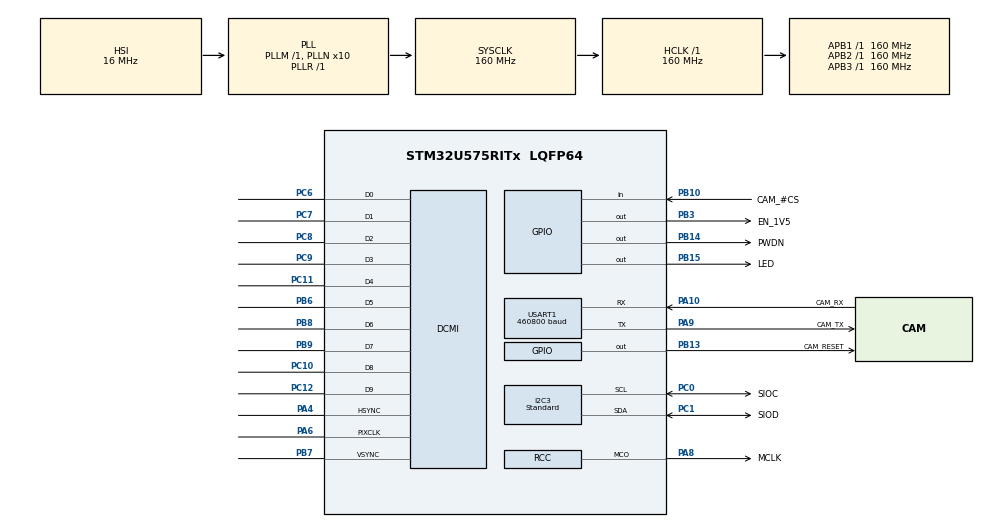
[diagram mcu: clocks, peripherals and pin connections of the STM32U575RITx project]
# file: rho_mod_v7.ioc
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CORTEX_M33_NS.userName=CORTEX_M33
DCMI.CaptureRate=DCMI_CR_ALL_FRAME
DCMI.HSPolarity=DCMI_HSPOLARITY_LOW
DCMI.JPEGMode=DCMI_JPEG_DISABLE
DCMI.LineSelectMode=DCMI_LSM_ALL
DCMI.PCKPolarity=DCMI_PCKPOLARITY_RISING
DCMI.VSPolarity=DCMI_VSPOLARITY_HIGH
GPDMA1.ChannelPRIV_GPDMACH15=DMA_CHANNEL_PRIV
GPDMA1.LINKALLOCATEDPORT_GPDMACH15=DMA_LINK_ALLOCATED_PORT1
GPDMA1.LINKEDLISTMODE_GPDMACH15=DMA_LINKEDLIST_CIRCULAR
GPDMA1.PRIORITY_LL_GPDMACH15=DMA_HIGH_PRIORITY
GPDMA1.TRANSFEREVENTMODE_LL_GPDMACH15=DMA_TCEM_LAST_LL_ITEM_TRANSFER
I2C3.I2C_Speed_Mode=I2C_Standard
I2C3.Timing=0x30909DEC
Linkedlist.MDMA_Channel0.GP_SW.0.ADDRESSING2D=ENABLE
Linkedlist.MDMA_Channel0.GP_SW.0.BlkDestAddrOffset=0
Linkedlist.MDMA_Channel0.GP_SW.0.BlkHWRequest=DMA_BREQ_SINGLE_BURST
Linkedlist.MDMA_Channel0.GP_SW.0.BlkSrcAddrOffset=0
Linkedlist.MDMA_Channel0.GP_SW.0.DataHandling=NONE
Linkedlist.MDMA_Channel0.GP_SW.0.DataSize=0
Linkedlist.MDMA_Channel0.GP_SW.0.DestAddrOffset=0
Linkedlist.MDMA_Channel0.GP_SW.0.DestBurstLength=1
Linkedlist.MDMA_Channel0.GP_SW.0.DestDataWidth=DMA_DEST_DATAWIDTH_WORD
Linkedlist.MDMA_Channel0.GP_SW.0.DestInc=DMA_DINC_INCREMENTED
Linkedlist.MDMA_Channel0.GP_SW.0.Direction=DMA_PERIPH_TO_MEMORY
Linkedlist.MDMA_Channel0.GP_SW.0.DstAddress=0
Linkedlist.MDMA_Channel0.GP_SW.0.Instance=MDMA_Channel0
Linkedlist.MDMA_Channel0.GP_SW.0.LL_CIRCULARNODE=DCMINode1
Linkedlist.MDMA_Channel0.GP_SW.0.LL_MASTERDMA=GPDMA2D
Linkedlist.MDMA_Channel0.GP_SW.0.LL_NAME=DCMIQueue
Linkedlist.MDMA_Channel0.GP_SW.0.LL_TYPE=CIRCULAR
Linkedlist.MDMA_Channel0.GP_SW.0.NODE_NAME=DCMINode1
Linkedlist.MDMA_Channel0.GP_SW.0.RepeatCount=1
Linkedlist.MDMA_Channel0.GP_SW.0.Requestforcodegen=GPDMA1_REQUEST_DCMI
Linkedlist.MDMA_Channel0.GP_SW.0.SrcAddrOffset=0
Linkedlist.MDMA_Channel0.GP_SW.0.SrcAddress=0
Linkedlist.MDMA_Channel0.GP_SW.0.SrcBurstLength=1
Linkedlist.MDMA_Channel0.GP_SW.0.SrcDataWidth=DMA_SRC_DATAWIDTH_WORD
Linkedlist.MDMA_Channel0.GP_SW.0.SrcInc=DMA_SINC_FIXED
Linkedlist.MDMA_Channel0.GP_SW.0.TransferAllocatedPortSrc=DMA_SRC_ALLOCATED_PORT0
Linkedlist.MDMA_Channel0.GP_SW.0.TransferEventMode=DMA_TCEM_BLOCK_TRANSFER
Linkedlist.MDMA_Channel0.GP_SW.0.TriggerPolarity=DMA_TRIG_POLARITY_MASKED
Linkedlist.MDMA_Channel0.GP_SW.1.ADDRESSING2D=ENABLE
Linkedlist.MDMA_Channel0.GP_SW.1.BlkDestAddrOffset=0
Linkedlist.MDMA_Channel0.GP_SW.1.BlkHWRequest=DMA_BREQ_SINGLE_BURST
Linkedlist.MDMA_Channel0.GP_SW.1.BlkSrcAddrOffset=0
Linkedlist.MDMA_Channel0.GP_SW.1.DataHandling=NONE
Linkedlist.MDMA_Channel0.GP_SW.1.DataSize=0
Linkedlist.MDMA_Channel0.GP_SW.1.DestAddrOffset=0
Linkedlist.MDMA_Channel0.GP_SW.1.DestBurstLength=1
Linkedlist.MDMA_Channel0.GP_SW.1.DestDataWidth=DMA_DEST_DATAWIDTH_WORD
Linkedlist.MDMA_Channel0.GP_SW.1.DestInc=DMA_DINC_INCREMENTED
Linkedlist.MDMA_Channel0.GP_SW.1.Direction=DMA_PERIPH_TO_MEMORY
Linkedlist.MDMA_Channel0.GP_SW.1.DstAddress=0
Linkedlist.MDMA_Channel0.GP_SW.1.Instance=MDMA_Channel0
Linkedlist.MDMA_Channel0.GP_SW.1.LL_CIRCULARNODE=DCMINode1
Linkedlist.MDMA_Channel0.GP_SW.1.LL_MASTERDMA=GPDMA2D
Linkedlist.MDMA_Channel0.GP_SW.1.LL_NAME=DCMIQueue
Linkedlist.MDMA_Channel0.GP_SW.1.LL_TYPE=CIRCULAR
Linkedlist.MDMA_Channel0.GP_SW.1.NODE_NAME=DCMINode2
Linkedlist.MDMA_Channel0.GP_SW.1.RepeatCount=1
Linkedlist.MDMA_Channel0.GP_SW.1.Requestforcodegen=GPDMA1_REQUEST_DCMI
Linkedlist.MDMA_Channel0.GP_SW.1.SrcAddrOffset=0
Linkedlist.MDMA_Channel0.GP_SW.1.SrcAddress=0
Linkedlist.MDMA_Channel0.GP_SW.1.SrcBurstLength=1
Linkedlist.MDMA_Channel0.GP_SW.1.SrcDataWidth=DMA_SRC_DATAWIDTH_WORD
Linkedlist.MDMA_Channel0.GP_SW.1.SrcInc=DMA_SINC_FIXED
Linkedlist.MDMA_Channel0.GP_SW.1.TransferAllocatedPortSrc=DMA_SRC_ALLOCATED_PORT0
Linkedlist.MDMA_Channel0.GP_SW.1.TransferEventMode=DMA_TCEM_BLOCK_TRANSFER
Linkedlist.MDMA_Channel0.GP_SW.1.TriggerPolarity=DMA_TRIG_POLARITY_MASKED
Linkedlist.MDMA_Channel0.Request0=GP_SW
Linkedlist.MDMA_Channel0.Request1=GP_SW
Linkedlist.MDMA_Channel0.RequestsNb=2
Linkedlist.RequestSet0=MDMA_Channel0
Linkedlist.RequestSetsNb=1
Mcu.Family=STM32U5
Mcu.Name=STM32U575RITx
Mcu.Package=LQFP64
NVIC.DCMI_PSSI_IRQn=true\:0\:0\:false\:false\:true\:true\:true\:true
NVIC.GPDMA1_Channel15_IRQn=true\:0\:0\:false\:false\:true\:true\:true\:true
NVIC.PriorityGroup=NVIC_PRIORITYGROUP_4
PA10.GPIO_Label=CAM_RX
PA10.Mode=Asynchronous
PA10.Signal=USART1_RX
PA13\ (JTMS/SWDIO).Mode=Serial_Wire
PA13\ (JTMS/SWDIO).Signal=DEBUG_JTMS-SWDIO
PA14\ (JTCK/SWCLK).Mode=Serial_Wire
PA14\ (JTCK/SWCLK).Signal=DEBUG_JTCK-SWCLK
PA4.GPIO_Speed=GPIO_SPEED_FREQ_HIGH
PA4.Mode=Slave_10_bits_External_Synchro
PA4.Signal=DCMI_HSYNC
PA6.GPIO_PuPd=GPIO_NOPULL
PA6.GPIO_Speed=GPIO_SPEED_FREQ_HIGH
PA6.Mode=Slave_10_bits_External_Synchro
PA6.Signal=DCMI_PIXCLK
PA8.GPIO_Label=MCLK
PA8.GPIO_Speed_HighF_Default=GPIO_SPEED_FREQ_VERY_HIGH
PA8.Mode=Clock-out
PA8.Signal=RCC_MCO
PA9.GPIO_Label=CAM_TX
PA9.Mode=Asynchronous
PA9.Signal=USART1_TX
PB10.GPIO_Label=CAM_\#CS
PB10.GPIO_PuPd=GPIO_PULLDOWN
PB10.Signal=GPIO_Input
PB13.GPIO_Label=CAM_RESET
PB13.GPIO_PuPd=GPIO_PULLDOWN
PB13.Signal=GPIO_Output
PB14.GPIO_Label=PWDN
PB14.GPIO_PuPd=GPIO_PULLUP
PB14.Signal=GPIO_Output
PB15.GPIO_Label=LED
PB15.GPIO_PuPd=GPIO_PULLDOWN
PB15.Signal=GPIO_Output
PB3\ (JTDO/TRACESWO).GPIO_Label=EN_1V5
PB3\ (JTDO/TRACESWO).Signal=GPIO_Output
PB6.GPIO_FM6=SYSCFG_FASTMODEPLUS_PB6
PB6.GPIO_PuPd=GPIO_NOPULL
PB6.GPIO_Speed=GPIO_SPEED_FREQ_HIGH
PB6.Mode=Slave_10_bits_External_Synchro
PB6.Signal=DCMI_D5
PB7.GPIO_FM6=__NULL
PB7.GPIO_FM7=SYSCFG_FASTMODEPLUS_PB7
PB7.GPIO_Speed=GPIO_SPEED_FREQ_HIGH
PB7.Mode=Slave_10_bits_External_Synchro
PB7.Signal=DCMI_VSYNC
PB8.GPIO_FM6=__NULL
PB8.GPIO_FM8=SYSCFG_FASTMODEPLUS_PB8
PB8.GPIO_PuPd=GPIO_NOPULL
PB8.GPIO_Speed=GPIO_SPEED_FREQ_HIGH
PB8.Mode=Slave_10_bits_External_Synchro
PB8.Signal=DCMI_D6
PB9.GPIO_FM6=__NULL
PB9.GPIO_FM9=SYSCFG_FASTMODEPLUS_PB9
PB9.GPIO_PuPd=GPIO_NOPULL
PB9.GPIO_Speed=GPIO_SPEED_FREQ_HIGH
PB9.Mode=Slave_10_bits_External_Synchro
PB9.Signal=DCMI_D7
PC0.GPIO_Label=SIOC
PC0.GPIO_Pu=GPIO_PULLUP
PC0.GPIO_Speed=GPIO_SPEED_FREQ_MEDIUM
PC0.Mode=I2C
PC0.Signal=I2C3_SCL
PC1.GPIO_Label=SIOD
PC1.GPIO_Pu=GPIO_PULLUP
PC1.GPIO_Speed=GPIO_SPEED_FREQ_MEDIUM
PC1.Mode=I2C
PC1.Signal=I2C3_SDA
PC10.GPIO_Speed=GPIO_SPEED_FREQ_HIGH
PC10.Mode=Slave_10_bits_External_Synchro
PC10.Signal=DCMI_D8
PC11.GPIO_PuPd=GPIO_NOPULL
PC11.GPIO_Speed=GPIO_SPEED_FREQ_HIGH
PC11.Mode=Slave_10_bits_External_Synchro
PC11.Signal=DCMI_D4
PC12.GPIO_Speed=GPIO_SPEED_FREQ_HIGH
PC12.Mode=Slave_10_bits_External_Synchro
PC12.Signal=DCMI_D9
PC14-OSC32_IN\ (PC14).Mode=LSE-External-Oscillator
PC14-OSC32_IN\ (PC14).Signal=RCC_OSC32_IN
PC15-OSC32_OUT\ (PC15).Mode=LSE-External-Oscillator
PC15-OSC32_OUT\ (PC15).Signal=RCC_OSC32_OUT
PC6.GPIO_PuPd=GPIO_NOPULL
PC6.GPIO_Speed=GPIO_SPEED_FREQ_HIGH
PC6.Mode=Slave_10_bits_External_Synchro
PC6.Signal=DCMI_D0
PC7.GPIO_PuPd=GPIO_NOPULL
PC7.GPIO_Speed=GPIO_SPEED_FREQ_HIGH
PC7.Mode=Slave_10_bits_External_Synchro
PC7.Signal=DCMI_D1
PC8.GPIO_PuPd=GPIO_NOPULL
PC8.GPIO_Speed=GPIO_SPEED_FREQ_HIGH
PC8.Mode=Slave_10_bits_External_Synchro
PC8.Signal=DCMI_D2
PC9.GPIO_PuPd=GPIO_NOPULL
PC9.GPIO_Speed=GPIO_SPEED_FREQ_HIGH
PC9.Mode=Slave_10_bits_External_Synchro
PC9.Signal=DCMI_D3
ProjectManager.HeapSize=0x200
ProjectManager.StackSize=0x400
ProjectManager.TargetToolchain=STM32CubeIDE
RCC.ADCFreq_Value=16000000
RCC.AHBFreq_Value=160000000
RCC.APB1Freq_Value=160000000
RCC.APB1TimFreq_Value=160000000
RCC.APB2Freq_Value=160000000
RCC.APB2TimFreq_Value=160000000
RCC.APB3Freq_Value=160000000
RCC.CortexFreq_Value=160000000
RCC.DACCLockSelectionVirtual=RCC_DAC1CLKSOURCE_LSI
RCC.DACCLockSelectionVirtualString=RCC_DAC1CLKSOURCE_LSI
RCC.EPOD_VALUE=16000000
RCC.HCLKFreq_Value=160000000
RCC.HSE_VALUE=16000000
RCC.HSI48_VALUE=48000000
RCC.HSI_VALUE=16000000
RCC.LSIDIV_VALUE=32000
RCC.MSIClockRange=RCC_MSIRANGE_2
RCC.MSI_VALUE=16000000
RCC.PLL1R=1
RCC.PLLFRACN=0
RCC.PLLN=10
RCC.PLLSourceVirtual=RCC_PLLSOURCE_HSI
RCC.RCC_MCO1SourceVirtual=RCC_MCO1SOURCE_HSI48
RCC.RCC_MCODiv=RCC_MCODIV_4
RCC.SYSCLKFreq_VALUE=160000000
RCC.SYSCLKSource=RCC_SYSCLKSOURCE_PLLCLK
RCC.USBFreq_Value=48000000
RCC.VCOOutputFreq_Value=160000000
USART1.BaudRate=460800
USART1.VirtualMode-Asynchronous=VM_ASYNC
VP_GPDMA1_VS_GPDMACH15.Mode=LINKEDLIST_GPDMACH15
VP_ICACHE_VS_ICACHE.Mode=DirectMappedCache
VP_PWR_VS_DBSignals.Mode=DisableDeadBatterySignals
VP_PWR_VS_SECSignals.Mode=Security/Privilege
board=custom

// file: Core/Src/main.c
/* USER CODE BEGIN Header */
/**
 ******************************************************************************
 * @file           : main.c
 * @brief          : Main program body
 ******************************************************************************
 * @attention
 *
 * <h2><center>&copy; Copyright (c) 2023 STMicroelectronics.
 * All rights reserved.</center></h2>
 *
 * This software component is licensed by ST under BSD 3-Clause license,
 * the "License"; You may not use this file except in compliance with the
 * License. You may obtain a copy of the License at:
 *                        opensource.org/licenses/BSD-3-Clause
 *
 ******************************************************************************
 */
/* USER CODE END Header */
#include "main.h"

/* USER CODE BEGIN Includes */
#include "linked_list.h"
#include "master.h"
/* USER CODE END Includes */

DCMI_HandleTypeDef hdcmi;

DMA_HandleTypeDef handle_GPDMA1_Channel15;

I2C_HandleTypeDef hi2c3;

UART_HandleTypeDef huart1;

/* USER CODE BEGIN PV */
extern DMA_QListTypeDef  DCMIQueue;

master_ios_t master_ios = { &hi2c3, &huart1, &hdcmi };
/* USER CODE END PV */

void SystemClock_Config(void);
static void SystemPower_Config(void);
static void MX_GPIO_Init(void);
static void MX_GPDMA1_Init(void);
static void MX_I2C3_Init(void);
static void MX_USART1_UART_Init(void);
static void MX_DCMI_Init(void);
static void MX_ICACHE_Init(void);

/* USER CODE BEGIN 0 */
int _write(int file, char *ptr, int len)
{
//	HAL_StatusTypeDef status = HAL_UART_Transmit(&huart1, (uint8_t*) ptr, len, 1000);
//	return (int) status;
	return 0;
}

/* USER CODE END 0 */

int main(void)
{

  /* MCU Configuration--------------------------------------------------------*/

  /* Reset of all peripherals, Initializes the Flash interface and the Systick. */
  HAL_Init();

  /* Configure the system clock */
  SystemClock_Config();

  /* Configure the System Power */
  SystemPower_Config();

  /* Initialize all configured peripherals */
  MX_GPIO_Init();
  MX_GPDMA1_Init();
  MX_I2C3_Init();
  MX_USART1_UART_Init();
  MX_DCMI_Init();
  MX_ICACHE_Init();
  /* USER CODE BEGIN 2 */
	MX_DCMIQueue_Config();
	HAL_DMAEx_List_LinkQ(&handle_GPDMA1_Channel15, &DCMIQueue);
	__HAL_LINKDMA(&hdcmi, DMA_Handle, handle_GPDMA1_Channel15);

	printf("Starting...\r\n");
	MasterFunctions.Connect(&master_ios);
  /* USER CODE END 2 */

  /* Infinite loop */
	while (1) {

	}
}

void SystemClock_Config(void)
{
  RCC_OscInitTypeDef RCC_OscInitStruct = {0};
  RCC_ClkInitTypeDef RCC_ClkInitStruct = {0};

  /** Configure the main internal regulator output voltage
  */
  if (HAL_PWREx_ControlVoltageScaling(PWR_REGULATOR_VOLTAGE_SCALE1) != HAL_OK)
  {
    Error_Handler();
  }

  /** Initializes the CPU, AHB and APB buses clocks
  */
  RCC_OscInitStruct.OscillatorType = RCC_OSCILLATORTYPE_HSI48|RCC_OSCILLATORTYPE_HSI;
  RCC_OscInitStruct.HSIState = RCC_HSI_ON;
  RCC_OscInitStruct.HSI48State = RCC_HSI48_ON;
  RCC_OscInitStruct.HSICalibrationValue = RCC_HSICALIBRATION_DEFAULT;
  RCC_OscInitStruct.PLL.PLLState = RCC_PLL_ON;
  RCC_OscInitStruct.PLL.PLLSource = RCC_PLLSOURCE_HSI;
  RCC_OscInitStruct.PLL.PLLMBOOST = RCC_PLLMBOOST_DIV1;
  RCC_OscInitStruct.PLL.PLLM = 1;
  RCC_OscInitStruct.PLL.PLLN = 10;
  RCC_OscInitStruct.PLL.PLLP = 2;
  RCC_OscInitStruct.PLL.PLLQ = 2;
  RCC_OscInitStruct.PLL.PLLR = 1;
  RCC_OscInitStruct.PLL.PLLRGE = RCC_PLLVCIRANGE_1;
  RCC_OscInitStruct.PLL.PLLFRACN = 0;
  if (HAL_RCC_OscConfig(&RCC_OscInitStruct) != HAL_OK)
  {
    Error_Handler();
  }

  /** Initializes the CPU, AHB and APB buses clocks
  */
  RCC_ClkInitStruct.ClockType = RCC_CLOCKTYPE_HCLK|RCC_CLOCKTYPE_SYSCLK
                              |RCC_CLOCKTYPE_PCLK1|RCC_CLOCKTYPE_PCLK2
                              |RCC_CLOCKTYPE_PCLK3;
  RCC_ClkInitStruct.SYSCLKSource = RCC_SYSCLKSOURCE_PLLCLK;
  RCC_ClkInitStruct.AHBCLKDivider = RCC_SYSCLK_DIV1;
  RCC_ClkInitStruct.APB1CLKDivider = RCC_HCLK_DIV1;
  RCC_ClkInitStruct.APB2CLKDivider = RCC_HCLK_DIV1;
  RCC_ClkInitStruct.APB3CLKDivider = RCC_HCLK_DIV1;

  if (HAL_RCC_ClockConfig(&RCC_ClkInitStruct, FLASH_LATENCY_4) != HAL_OK)
  {
    Error_Handler();
  }

  /** MCO configuration
  */
  HAL_RCC_MCOConfig(RCC_MCO1, RCC_MCO1SOURCE_HSI48, RCC_MCODIV_4);
}

/**
  * @brief Power Configuration
  * @retval None
  */
static void SystemPower_Config(void)
{

  /*
   * Disable the internal Pull-Up in Dead Battery pins of UCPD peripheral
   */
  HAL_PWREx_DisableUCPDDeadBattery();
}

static void MX_DCMI_Init(void)
{

  hdcmi.Instance = DCMI;
  hdcmi.Init.SynchroMode = DCMI_SYNCHRO_HARDWARE;
  hdcmi.Init.PCKPolarity = DCMI_PCKPOLARITY_RISING;
  hdcmi.Init.VSPolarity = DCMI_VSPOLARITY_HIGH;
  hdcmi.Init.HSPolarity = DCMI_HSPOLARITY_LOW;
  hdcmi.Init.CaptureRate = DCMI_CR_ALL_FRAME;
  hdcmi.Init.ExtendedDataMode = DCMI_EXTEND_DATA_10B;
  hdcmi.Init.JPEGMode = DCMI_JPEG_DISABLE;
  hdcmi.Init.ByteSelectMode = DCMI_BSM_ALL;
  hdcmi.Init.ByteSelectStart = DCMI_OEBS_ODD;
  hdcmi.Init.LineSelectMode = DCMI_LSM_ALL;
  hdcmi.Init.LineSelectStart = DCMI_OELS_ODD;
  if (HAL_DCMI_Init(&hdcmi) != HAL_OK)
  {
    Error_Handler();
  }

}

static void MX_GPDMA1_Init(void)
{

  /* Peripheral clock enable */
  __HAL_RCC_GPDMA1_CLK_ENABLE();

  /* GPDMA1 interrupt Init */
    HAL_NVIC_SetPriority(GPDMA1_Channel15_IRQn, 0, 0);
    HAL_NVIC_EnableIRQ(GPDMA1_Channel15_IRQn);

  handle_GPDMA1_Channel15.Instance = GPDMA1_Channel15;
  handle_GPDMA1_Channel15.InitLinkedList.Priority = DMA_HIGH_PRIORITY;
  handle_GPDMA1_Channel15.InitLinkedList.LinkStepMode = DMA_LSM_FULL_EXECUTION;
  handle_GPDMA1_Channel15.InitLinkedList.LinkAllocatedPort = DMA_LINK_ALLOCATED_PORT1;
  handle_GPDMA1_Channel15.InitLinkedList.TransferEventMode = DMA_TCEM_LAST_LL_ITEM_TRANSFER;
  handle_GPDMA1_Channel15.InitLinkedList.LinkedListMode = DMA_LINKEDLIST_CIRCULAR;
  if (HAL_DMAEx_List_Init(&handle_GPDMA1_Channel15) != HAL_OK)
  {
    Error_Handler();
  }
  if (HAL_DMA_ConfigChannelAttributes(&handle_GPDMA1_Channel15, DMA_CHANNEL_PRIV) != HAL_OK)
  {
    Error_Handler();
  }

}

static void MX_I2C3_Init(void)
{

  hi2c3.Instance = I2C3;
  hi2c3.Init.Timing = 0x30909DEC;
  hi2c3.Init.OwnAddress1 = 0;
  hi2c3.Init.AddressingMode = I2C_ADDRESSINGMODE_7BIT;
  hi2c3.Init.DualAddressMode = I2C_DUALADDRESS_DISABLE;
  hi2c3.Init.OwnAddress2 = 0;
  hi2c3.Init.OwnAddress2Masks = I2C_OA2_NOMASK;
  hi2c3.Init.GeneralCallMode = I2C_GENERALCALL_DISABLE;
  hi2c3.Init.NoStretchMode = I2C_NOSTRETCH_DISABLE;
  if (HAL_I2C_Init(&hi2c3) != HAL_OK)
  {
    Error_Handler();
  }

  /** Configure Analogue filter
  */
  if (HAL_I2CEx_ConfigAnalogFilter(&hi2c3, I2C_ANALOGFILTER_ENABLE) != HAL_OK)
  {
    Error_Handler();
  }

  /** Configure Digital filter
  */
  if (HAL_I2CEx_ConfigDigitalFilter(&hi2c3, 0) != HAL_OK)
  {
    Error_Handler();
  }

}

static void MX_ICACHE_Init(void)
{

  /** Enable instruction cache in 1-way (direct mapped cache)
  */
  if (HAL_ICACHE_ConfigAssociativityMode(ICACHE_1WAY) != HAL_OK)
  {
    Error_Handler();
  }
  if (HAL_ICACHE_Enable() != HAL_OK)
  {
    Error_Handler();
  }

}

static void MX_USART1_UART_Init(void)
{

  huart1.Instance = USART1;
  huart1.Init.BaudRate = 460800;
  huart1.Init.WordLength = UART_WORDLENGTH_8B;
  huart1.Init.StopBits = UART_STOPBITS_1;
  huart1.Init.Parity = UART_PARITY_NONE;
  huart1.Init.Mode = UART_MODE_TX_RX;
  huart1.Init.HwFlowCtl = UART_HWCONTROL_NONE;
  huart1.Init.OverSampling = UART_OVERSAMPLING_16;
  huart1.Init.OneBitSampling = UART_ONE_BIT_SAMPLE_DISABLE;
  huart1.Init.ClockPrescaler = UART_PRESCALER_DIV1;
  huart1.AdvancedInit.AdvFeatureInit = UART_ADVFEATURE_NO_INIT;
  if (HAL_UART_Init(&huart1) != HAL_OK)
  {
    Error_Handler();
  }
  if (HAL_UARTEx_SetTxFifoThreshold(&huart1, UART_TXFIFO_THRESHOLD_1_8) != HAL_OK)
  {
    Error_Handler();
  }
  if (HAL_UARTEx_SetRxFifoThreshold(&huart1, UART_RXFIFO_THRESHOLD_1_8) != HAL_OK)
  {
    Error_Handler();
  }
  if (HAL_UARTEx_DisableFifoMode(&huart1) != HAL_OK)
  {
    Error_Handler();
  }

}

static void MX_GPIO_Init(void)
{
  GPIO_InitTypeDef GPIO_InitStruct = {0};

  /* GPIO Ports Clock Enable */
  __HAL_RCC_GPIOC_CLK_ENABLE();
  __HAL_RCC_GPIOA_CLK_ENABLE();
  __HAL_RCC_GPIOB_CLK_ENABLE();

  /*Configure GPIO pin Output Level */
  HAL_GPIO_WritePin(GPIOB, CAM_RESET_Pin|PWDN_Pin|LED_Pin|EN_1V5_Pin, GPIO_PIN_RESET);

  /*Configure GPIO pin : CAM__CS_Pin */
  GPIO_InitStruct.Pin = CAM__CS_Pin;
  GPIO_InitStruct.Mode = GPIO_MODE_INPUT;
  GPIO_InitStruct.Pull = GPIO_PULLDOWN;
  HAL_GPIO_Init(CAM__CS_GPIO_Port, &GPIO_InitStruct);

  /*Configure GPIO pins : CAM_RESET_Pin LED_Pin */
  GPIO_InitStruct.Pin = CAM_RESET_Pin|LED_Pin;
  GPIO_InitStruct.Mode = GPIO_MODE_OUTPUT_PP;
  GPIO_InitStruct.Pull = GPIO_PULLDOWN;
  GPIO_InitStruct.Speed = GPIO_SPEED_FREQ_LOW;
  HAL_GPIO_Init(GPIOB, &GPIO_InitStruct);

  /*Configure GPIO pin : PWDN_Pin */
  GPIO_InitStruct.Pin = PWDN_Pin;
  GPIO_InitStruct.Mode = GPIO_MODE_OUTPUT_PP;
  GPIO_InitStruct.Pull = GPIO_PULLUP;
  GPIO_InitStruct.Speed = GPIO_SPEED_FREQ_LOW;
  HAL_GPIO_Init(PWDN_GPIO_Port, &GPIO_InitStruct);

  /*Configure GPIO pin : MCLK_Pin */
  GPIO_InitStruct.Pin = MCLK_Pin;
  GPIO_InitStruct.Mode = GPIO_MODE_AF_PP;
  GPIO_InitStruct.Pull = GPIO_NOPULL;
  GPIO_InitStruct.Speed = GPIO_SPEED_FREQ_VERY_HIGH;
  GPIO_InitStruct.Alternate = GPIO_AF0_MCO;
  HAL_GPIO_Init(MCLK_GPIO_Port, &GPIO_InitStruct);

  /*Configure GPIO pin : EN_1V5_Pin */
  GPIO_InitStruct.Pin = EN_1V5_Pin;
  GPIO_InitStruct.Mode = GPIO_MODE_OUTPUT_PP;
  GPIO_InitStruct.Pull = GPIO_NOPULL;
  GPIO_InitStruct.Speed = GPIO_SPEED_FREQ_LOW;
  HAL_GPIO_Init(EN_1V5_GPIO_Port, &GPIO_InitStruct);

}

void Error_Handler(void)
{
	__disable_irq();
	while (1) {
	}
}
